# NUC505_v1 register map
File version: 1.0
Registers are 32-bit, read-write, reset 0x0 unless marked. A register's access mark holds for its fields unless they carry their own. Offsets are from the block's base; [hi:lo] are bit positions; {n}, {i} and the like mark numbered series; 'fields as' and 'values as' point back to an identical list.

## UART0 — UART Register Map
Base 0x400EC000
0x00 UART_DAT reset not defined — UART Receive/Transmit Buffer Register
  [7:0] DAT — Receiving/Transmit Buffer. Write Operation: By writing one byte to this register, the data byte will be stored in transmitter FIFO. The UART Controller will send out the data stored in transmitter FIFO top location through the UART_TXD. Read Operation: By reading this register, the UART will return an 8-bit data received from receiving FIFO.
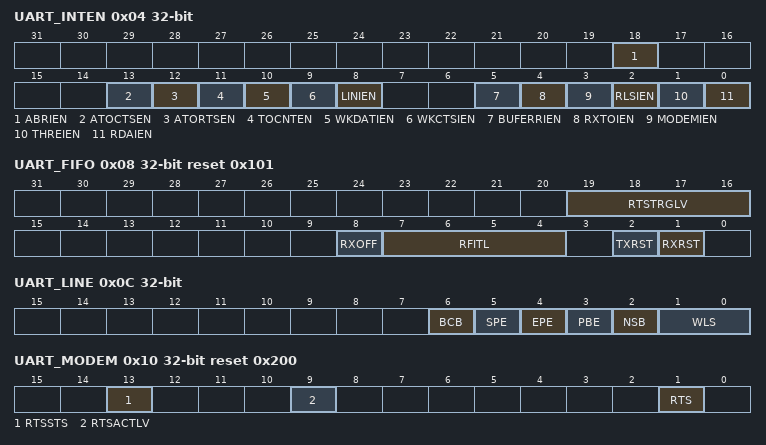
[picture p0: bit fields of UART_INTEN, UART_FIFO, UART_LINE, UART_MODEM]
0x04 UART_INTEN — UART Interrupt Enable Register
  [18] ABRIEN — Auto-baud Rate Interrupt Enable Control
    0=Auto-baud rate interrupt Disabled; 1=Auto-baud rate interrupt Enabled
  [13] ATOCTSEN — nCTS Auto-flow Control Enable Control. When nCTS auto-flow is enabled, the UART will send data to external device if nCTS input assert (UART will not send data to device until nCTS is asserted).
    0=nCTS auto-flow control Disabled; 1=nCTS auto-flow control Enabled
  [12] ATORTSEN — nRTS Auto-flow Control Enable Control. When nRTS auto-flow is enabled, if the number of bytes in the RX FIFO equals the RTSTRGLV (UART_FIFO[19:16]), the UART will de-assert nRTS signal.
    0=nRTS auto-flow control Disabled; 1=nRTS auto-flow control Enabled
  [11] TOCNTEN — Time-out Counter Enable Control
    0=Time-out counter Disabled; 1=Time-out counter Enabled
  [10] WKDATIEN — Incoming Data Wake-up Interrupt Enable Control. Hardware will clear this bit when the incoming data wake-up operation finishes and "system clock" work stable.
    0=Incoming data wake-up system function Disabled; 1=Incoming data wake-up system function Enabled. When the system is in Power-down mode, incoming data will wake up system from Power-down mode.
  [9] WKCTSIEN — nCTS Wake-up Interrupt Enable Control
    0=nCTS wake-up system function Disabled; 1=Wake-up system function Enabled. When the system is in Power-down mode, an external nCTS change will wake up system from Power-down mode
  [8] LINIEN — LIN Bus Interrupt Enable Control (Not Available in UART1/UART2). This bit is used for LIN function mode.
    0=LIN bus interrupt Disabled; 1=LIN bus interrupt Enabled
  [5] BUFERRIEN — Buffer Error Interrupt Enable Control
    0=Buffer error interrupt Disabled; 1=Buffer error interrupt Enabled
  [4] RXTOIEN — RX Time-out Interrupt Enable Control
    0=RX time-out interrupt Disabled; 1=RX time-out interrupt Enabled
  [3] MODEMIEN — Modem Status Interrupt Enable Control
    0=Modem status interrupt Disabled; 1=Modem status interrupt Enabled
  [2] RLSIEN — Receive Line Status Interrupt Enable Control
    0=Receive Line Status interrupt Disabled; 1=Receive Line Status interrupt Enabled
  [1] THREIEN — Transmit Holding Register Empty Interrupt Enable Control
    0=Transmit holding register empty interrupt Disabled; 1=Transmit holding register empty interrupt Enabled
  [0] RDAIEN — Receive Data Available Interrupt Enable Control
    0=Receive data available interrupt Disabled; 1=Receive data available interrupt Enabled
0x08 UART_FIFO reset 0x101 — UART FIFO Control Register
  [19:16] RTSTRGLV — nRTS Trigger Level for Auto-flow Control Use. Note: This field is used for automatic nRTS flow control.
    0=nRTS Trigger Level is 1 bytes; 1=nRTS Trigger Level is 4bytes; 2=nRTS Trigger Level is 8 bytes; 3=nRTS Trigger Level is 14 bytes; 4=nRTS Trigger Level is 30/14 (64 FIFO/16 FIFO); 5=nRTS Trigger Level is 46/14 (64 FIFO/16 FIFO); 6=nRTS Trigger Level is 62/14 (64 FIFO/16 FIFO)
  [8] RXOFF — Receiver Disable Control. The receiver is disabled or not (set 1 to disable receiver). Note: This bit is used for RS-485 Normal Multi-drop mode. It should be programmed before RS485NMM (UART_ALTCTL [8]) is programmed.
    0=Receiver Enabled; 1=Receiver Disabled
  [7:4] RFITL — RX FIFO Interrupt Trigger Level. When the number of bytes in the receive FIFO equals the RFITL, the RDAIF will be set (if RDAIEN (UART_INTEN [0]) enabled, and an interrupt will be generated).
    0=RX FIFO Interrupt Trigger Level is 1 byte; 1=RX FIFO Interrupt Trigger Level is 4 bytes; 2=RX FIFO Interrupt Trigger Level is 8 bytes; 3=RX FIFO Interrupt Trigger Level is 14 bytes; 4=RX FIFO Interrupt Trigger Level is 30/14 (64 FIFO/16 FIFO); 5=RX FIFO Interrupt Trigger Level is 46/14 (64 FIFO/16 FIFO); 6=RX FIFO Interrupt Trigger Level is 62/14 (64 FIFO/16 FIFO)
  [2] TXRST — TX Field Software Reset Control. When TXRST (UART_FIFO[2]) is set, all the byte in the transmit FIFO and TX internal state machine are cleared. Note: This bit will automatically clear at least 3 UART peripheral clock cycles.
    0=No effect; 1=Reset the TX internal state machine and pointers
  [1] RXRST — RX Field Software Reset Control. When RXRST (UART_FIFO[1]) is set, all the byte in the receiver FIFO and RX internal state machine are cleared. Note: This bit will automatically clear at least 3 UART peripheral clock cycles.
    0=No effect; 1=Reset the RX internal state machine and pointers
0x0C UART_LINE — UART Line Control Register
  [6] BCB — Break Control. Note: When this bit is set to logic 1, the serial data output (TX) is forced to the Spacing State (logic 0). This bit acts only on TX line and has no effect on the transmitter logic.
    0=Break Control Disabled; 1=Break Control Enabled
  [5] SPE — Stick Parity Enable Control. Note: If PBE (UART_LINE[3]) and EPE (UART_LINE[4]) are logic 1, the parity bit is transmitted and checked as logic 0. If PBE (UART_LINE[3]) is 1 and EPE (UART_LINE[4]) is 0 then the parity bit is transmitted and checked as 1.
    0=Stick parity Disabled; 1=Stick parity Enabled
  [4] EPE — Even Parity Enable Control. Note: This bit is effective only when PBE (UART_LINE[3]) is set.
    0=Odd number of logic 1's is transmitted and checked in each word; 1=Even number of logic 1's is transmitted and checked in each word
  [3] PBE — Parity Bit Enable Control. Note: Parity bit is generated on each outgoing character and is checked on each incoming data.
    0=No parity bit generated Disabled; 1=Parity bit generated Enabled
  [2] NSB — Number of "STOP Bit"
    0=One "STOP bit" is generated in the transmitted data; 1=When select 5-bit word length, 1.5 "STOP bit" is generated in the transmitted data. When select 6-, 7- and 8-bit word length, 2 "STOP bit" is generated in the transmitted data
  [1:0] WLS — Word Length Selection. This field sets UART word length.
    {v}={v+5} bits (v=0..3)
0x10 UART_MODEM reset 0x200 — UART Modem Control Register
  [13] RTSSTS ro — nRTS Pin Status (Read Only). This bit mirror from nRTS pin output of voltage logic status.
    0=nRTS pin output is low level voltage logic state; 1=nRTS pin output is high level voltage logic state
  [9] RTSACTLV — nRTS Pin Active Level. This bit defines the active level state of nRTS pin output. Note1: Refer to Figure 6.1010 and Figure 6.1011 for UART function mode. Note2: Refer to Figure 6.1021 and Figure 6.1022 for RS-485 function mode.
    0=nRTS pin output is high level active; 1=nRTS pin output is low level active. (Default)
  [1] RTS — nRTS (Request-to-send) Signal Control. This bit is direct control internal nRTS signal active or not, and then drive the nRTS pin output with RTSACTLV bit configuration. Note1: This nRTS signal control bit is not effective when nRTS auto-flow control is enabled in UART function mode. Note2: This nRTS signal control bit is not effective when RS-485 auto direction mode (AUD) is enabled in RS-485 function mode.
    0=nRTS signal is active; 1=nRTS signal is inactive
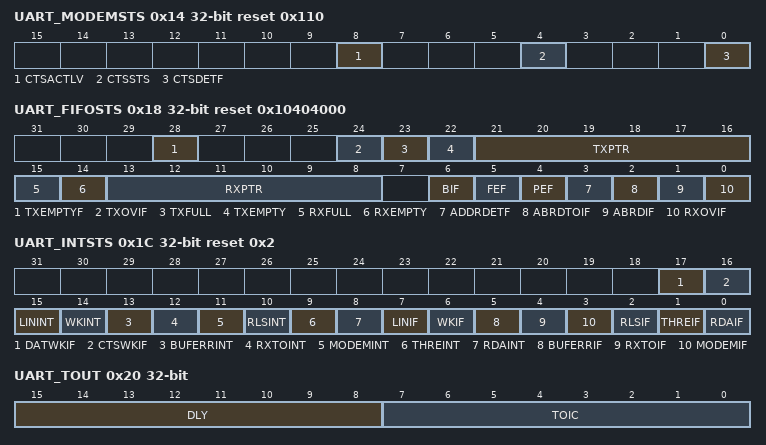
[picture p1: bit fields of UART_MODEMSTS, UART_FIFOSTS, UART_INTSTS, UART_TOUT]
0x14 UART_MODEMSTS reset 0x110 — UART Modem Status Register
  [8] CTSACTLV — nCTS Pin Active Level. This bit defines the active level state of nCTS pin input.
    0=nCTS pin input is high level active; 1=nCTS pin input is low level active. (Default)
  [4] CTSSTS ro — nCTS Pin Status (Read Only). This bit mirror from nCTS pin input of voltage logic status. Note: This bit echoes when UART Controller peripheral clock is enabled, and nCTS multi-function port is selected.
    0=nCTS pin input is low level voltage logic state; 1=nCTS pin input is high level voltage logic state
  [0] CTSDETF ro — Detect nCTS State Change Flag (Read Only). This bit is set whenever nCTS input has change state, and it will generate Modem interrupt to CPU when MODEMIEN (UART_INTEN [3]) is set to 1. Note: This bit is read only, but can be cleared by writing "1" to it.
    0=nCTS input has not change state; 1=nCTS input has change state
0x18 UART_FIFOSTS reset 0x10404000 — UART FIFO Status Register
  [28] TXEMPTYF ro — Transmitter Empty Flag (Read Only). This bit is set by hardware when TX FIFO (UART_DAT) is empty and the STOP bit of the last byte has been transmitted. Note: This bit is cleared automatically when TX FIFO is not empty or the last byte transmission has not completed.
    0=TX FIFO is not empty; 1=TX FIFO is empty
  [24] TXOVIF ro — TX Overflow Error Interrupt Flag (Read Only). If TX FIFO (UART_DAT) is full, an additional write to UART_DAT will cause this bit to logic 1. Note: This bit is read only, but can be cleared by writing "1" to it.
    0=TX FIFO is not overflow; 1=TX FIFO is overflow
  [23] TXFULL ro — Transmitter FIFO Full (Read Only). This bit indicates TX FIFO full or not. Note: This bit is set when the number of usage in TX FIFO Buffer is equal to 16/64, otherwise is cleared by hardware.
    0=TX FIFO is not full; 1=TX FIFO is full
  [22] TXEMPTY ro — Transmitter FIFO Empty (Read Only). This bit indicates TX FIFO empty or not. Note: When the last byte of TX FIFO has been transferred to Transmitter Shift Register, hardware sets this bit high. It will be cleared when writing data into DAT (TX FIFO not empty).
    0=TX FIFO is not empty; 1=TX FIFO is empty
  [21:16] TXPTR ro — TX FIFO Pointer (Read Only). This field indicates the TX FIFO Buffer Pointer. When CPU writes one byte into UART_DAT, TXPTR increases one. When one byte of TX FIFO is transferred to Transmitter Shift Register, TXPTR decreases one. The Maximum value shown in TXPTR is 15/63. When the using level of TX FIFO Buffer equal to 16/64, the TXFULL bit is set to 1 and TXPTR will show 0. As one byte of TX FIFO is transferred to Transmitter Shift Register, the TXFULL bit is cleared to 0 and TXPTR will show 15/63.
  [15] RXFULL ro — Receiver FIFO Full (Read Only). This bit initiates RX FIFO full or not. Note: This bit is set when the number of usage in RX FIFO Buffer is equal to 16/64, otherwise is cleared by hardware.
    0=RX FIFO is not full; 1=RX FIFO is full
  [14] RXEMPTY ro — Receiver FIFO Empty (Read Only). This bit initiate RX FIFO empty or not. Note: When the last byte of RX FIFO has been read by CPU, hardware sets this bit high. It will be cleared when UART receives any new data.
    0=RX FIFO is not empty; 1=RX FIFO is empty
  [13:8] RXPTR ro — RX FIFO Pointer (Read Only). This field indicates the RX FIFO Buffer Pointer. When UART receives one byte from external device, RXPTR increases one. When one byte of RX FIFO is read by CPU, RXPTR decreases one. The Maximum value shown in RXPTR is 15/63. When the using level of RX FIFO Buffer equal to 16/64, the RXFULL bit is set to 1 and RXPTR will show 0. As one byte of RX FIFO is read by CPU, the RXFULL bit is cleared to 0 and RXPTR will show 15/63.
  [6] BIF ro — Break Interrupt Flag (Read Only). This bit is set to logic 1 whenever the received data input (RX) is held in the "spacing state" (logic 0) for longer than a full word transmission time (that is, the total time of "start bit" + data bits + parity + stop bits). Note: This bit is read only, but can be cleared by writing '1' to it.
    0=No Break interrupt is generated; 1=Break interrupt is generated
  [5] FEF ro — Framing Error Flag (Read Only). This bit is set to logic 1 whenever the received character does not have a valid "stop bit" (that is, the stop bit following the last data bit or parity bit is detected as logic 0). Note: This bit is read only, but can be cleared by writing '1' to it.
    0=No framing error is generated; 1=Framing error is generated
  [4] PEF ro — Parity Error Flag (Read Only). This bit is set to logic 1 whenever the received character does not have a valid "parity bit". Note: This bit is read only, but can be cleared by writing '1' to it.
    0=No parity error is generated; 1=Parity error is generated
  [3] ADDRDETF ro — RS-485 Address Byte Detect Flag (Read Only). Note1: This field is used for RS-485 function mode and ADDRDEN (UART_ALTCTL[15]) is set to 1 to enable Address detection mode. Note2: This bit is read only, but can be cleared by writing '1' to it.
    0=Receiver detects a data that is not an address bit (bit 9 ='0'); 1=Receiver detects a data that is an address bit (bit 9 ='1')
  [2] ABRDTOIF ro — Auto-baud Rate Time-out Interrupt (Read Only). Note1: This bit is set to logic "1" in Auto-baud Rate Detect mode and the baud rate counter is overflow. Note2: This bit is read only, but can be cleared by writing "1" to it.
    0=Auto-baud rate counter is underflow; 1=Auto-baud rate counter is overflow
  [1] ABRDIF ro — Auto-baud Rate Detect Interrupt (Read Only). Note1: This bit is set to logic "1" when auto-baud rate detect function is finished. Note2: This bit is read only, but can be cleared by writing "1" to it.
    0=Auto-baud rate detect function is not finished; 1=Auto-baud rate detect function is finished
  [0] RXOVIF ro — RX Overflow Error Interrupt Flag (Read Only). This bit is set when RX FIFO overflow. If the number of bytes of received data is greater than RX_FIFO (UART_DAT) size, 16/64 bytes this bit will be set. Note: This bit is read only, but can be cleared by writing "1" to it.
    0=RX FIFO is not overflow; 1=RX FIFO is overflow
0x1C UART_INTSTS reset 0x2 — UART Interrupt Status Register
  [17] DATWKIF ro — Data Wake-up Interrupt Flag (Read Only). This bit is set if chip wake-up from Power-down state by data wake-up. Note1: If WKDATIEN (UART_INTEN[10]) is enabled, the wake-up interrupt is generated. Note2: This bit is read only, but can be cleared by writing '1' to it.
    0=Chip stays in Power-down state; 1=Chip wake-up from Power-down state by data wake-up
  [16] CTSWKIF ro — nCTS Wake-up Interrupt Flag (Read Only). Note1: If WKCTSIEN (UART_INTEN[9])is enabled, the wake-up interrupt is generated. Note2: This bit is read only, but can be cleared by writing '1' to it.
    0=Chip stays in Power-down state; 1=Chip wake-up from Power-down state by nCTS wake-up
  [15] LININT ro — LIN Bus Interrupt Indicator (Read Only)(Not Available in UART0 Channel). This bit is set if LINIEN (UART_INTEN[8]) and LIN IF(UART_INTSTS[7]) are both set to 1.
    0=No LIN Bus interrupt is generated; 1=The LIN Bus interrupt is generated
  [14] WKINT ro — UART Wake-up Interrupt Indicator (Read Only). This bit is set when DATWKIF or CTSWKIF is set to 1.
    0=NO data or nCTS wake-up interrupt are generated; 1=Data or nCTS wake-up interrupt are generated
  [13] BUFERRINT ro — Buffer Error Interrupt Indicator (Read Only). This bit is set if BFERRIEN(UART_INTEN[5] and BUFERRIF(UART_INTSTS[5]) are both set to 1.
    0=No buffer error interrupt is generated; 1=Buffer error interrupt is generated
  [12] RXTOINT ro — Time-out Interrupt Indicator (Read Only). This bit is set if TOUTIEN(UART_INTEN[4]) and RXTOIF(UART_INTSTS[4]) are both set to 1.
    0=No Tout interrupt is generated; 1=Tout interrupt is generated
  [11] MODEMINT ro — MODEM Status Interrupt Indicator (Read Only). This bit is set if MODEMIEN(UART_INTEN[3] and MODEMIF(UART_INTSTS[4]) are both set to 1
    0=No Modem interrupt is generated; 1=Modem interrupt is generated
  [10] RLSINT ro — Receive Line Status Interrupt Indicator (Read Only). This bit is set if RLSIEN (UART_INTEN[2]) and RLSIF(UART_INTSTS[2]) are both set to 1.
    0=No RLS interrupt is generated; 1=RLS interrupt is generated
  [9] THREINT ro — Transmit Holding Register Empty Interrupt Indicator (Read Only). This bit is set if THREIEN (UART_INTEN[1])and THREIF(UART_INTSTS[1]) are both set to 1.
    0=No DATE interrupt is generated; 1=DATE interrupt is generated
  [8] RDAINT ro — Receive Data Available Interrupt Indicator (Read Only). This bit is set if RDAIEN (UART_INTEN[0]) and RDAIF (UART_INTSTS[0]) are both set to 1.
    0=No RDA interrupt is generated; 1=RDA interrupt is generated
  [7] LINIF ro — LIN Bus Interrupt Flag (Read Only) (Not Available in UART0 Channel). Note: This bit is read only. This bit is cleared when SLVHDETF(UART_LINSTS[0]), BRKDETF(UART_LINSTS[8]), BITEF(UART_LINSTS[9]), SLVIDPEF (UART_LINSTS[2]), SLVHEF(UART_LINSTS[1]) and SLVSYNCF(UART_LINSTS[3]) all are cleared.
    0=None of SLVHDETF, BRKDETF, BITEF, SLVIDPEF and SLVHEF is generated; 1=At least one of SLVHDETF, BRKDETF, BITEF, SLVIDPEF and SLVHEF is generated
  [6] WKIF ro — UART Wake-up Interrupt Flag (Read Only). This bit is set when DATWKIF (UART_INTSTS[17]) or CTSWKIF(UART_INTSTS[16]) is set to 1. Note: This bit is read only. This bit is cleared if both of DATWKIF (UART_INTSTS[17]) and CTSWKIF(UART_INTSTS[16]) are cleared to 0 by writing 1 to DATWKIF (UART_INTSTS[17]) and CTSWKIF (UART_INTSTS[17]).
    0=No DATWKIF and CTSWKIF are generated; 1=DATWKIF or CTSWKIF
  [5] BUFERRIF ro — Buffer Error Interrupt Flag (Read Only). This bit is set when the TX FIFO or RX FIFO overflows (TXOVIF (UART_FIFOSTS[24]) or RXOVIF (UART_FIFOSTS[0]) is set). When BUFERRIF (UART_INTSTS[5])is set, the transfer is not correct. If BFERRIEN (UART_INTEN [8]) is enabled, the buffer error interrupt will be generated. Note: This bit is read only. This bit is cleared if both of RXOVIF(UART_FIFOSTS[0]) and TXOVIF(UART_FIFOSTS[24]) are cleared to 0 by writing 1 to RXOVIF(UART_FIFOSTS[0]) and TXOVIF(UART_FIFOSTS[24]).
    0=No buffer error interrupt flag is generated; 1=Buffer error interrupt flag is generated
  [4] RXTOIF ro — Time-out Interrupt Flag (Read Only). This bit is set when the RX FIFO is not empty and no activities occurred in the RX FIFO and the time-out counter equal to TOIC. If TOUTIEN (UART_INTEN [4]) is enabled, the Tout interrupt will be generated. Note: This bit is read only and user can read UART_DAT (RX is in active) to clear it.
    0=No Time-out interrupt flag is generated; 1=Time-out interrupt flag is generated
  [3] MODEMIF ro — MODEM Interrupt Flag (Read Only) Channel. Note: This bit is read only and reset to 0 when bit CTSDETF is cleared by a write 1 on CTSDETF(UART_MODEMSTS[0]).
    0=No Modem interrupt flag is generated; 1=Modem interrupt flag is generated
  [2] RLSIF ro — Receive Line Interrupt Flag (Read Only). This bit is set when the RX receive data have parity error, frame error or break error (at least one of 3 bits, BIF(UART_FIFOSTS[6]), FEF(UART_FIFOSTS[5]) and PEF(UART_FIFOSTS[4]), is set). If RLSIEN (UART_INTEN [2]) is enabled, the RLS interrupt will be generated. Note2: This bit is read only and reset to 0 when all bits of BIF (UART_FIFOSTS[6]), FEF(UART_FIFOSTS[5]) and PEF(UART_FIFOSTS[4]) are cleared. Note3: In RS-485 function mode, this bit is read only and reset to 0 when all bits of BIF (UART_FIFOSTS[6]) , FEF(UART_FIFOSTS[5]) and PEF(UART_FIFOSTS[4]) and ADDRDETF (UART_FIFOSTS[3]) are cleared.
    0=No RLS interrupt flag is generated; 1=RLS interrupt flag is generated
  [1] THREIF ro — Transmit Holding Register Empty Interrupt Flag (Read Only). This bit is set when the last data of TX FIFO is transferred to Transmitter Shift Register. If THREIEN (UART_INTEN[1]) is enabled, the THRE interrupt will be generated. Note: This bit is read only and it will be cleared when writing data into UART_DAT (TX FIFO not empty).
    0=No THRE interrupt flag is generated; 1=THRE interrupt flag is generated
  [0] RDAIF ro — Receive Data Available Interrupt Flag (Read Only). When the number of bytes in the RX FIFO equals the RFITL then the RDAIF(UART_INTSTS[0]) will be set. If RDAIEN (UART_INTEN [0]) is enabled, the RDA interrupt will be generated. Note: This bit is read only and it will be cleared when the number of unread bytes of RX FIFO drops below the threshold level (RFITL(UART_FIFO[7:4]).
    0=No RDA interrupt flag is generated; 1=RDA interrupt flag is generated
0x20 UART_TOUT — UART Time-out Register
  [15:8] DLY — TX Delay Time Value. This field is used to programming the transfer delay time between the last stop bit and next start bit. The unit is bit time.
  [7:0] TOIC — Time-out Interrupt Comparator
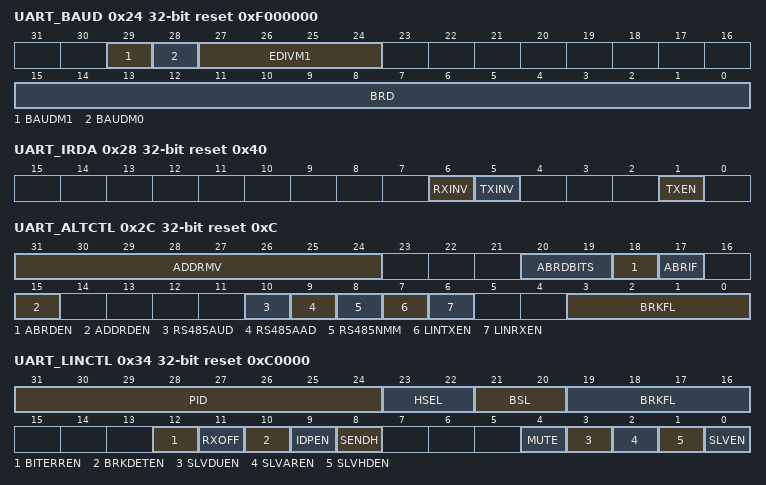
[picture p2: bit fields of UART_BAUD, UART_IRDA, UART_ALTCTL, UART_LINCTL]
0x24 UART_BAUD reset 0xF000000 — UART Baud Rate Divisor Register
  [29] BAUDM1 — BAUD Rate Mode Selection Bit 1. This bit is baud rate mode selection bit 1. UART provides three baud rate calculation modes. This bit combines with BAUDM0 (UART_BAUD[28]) to select baud rate calculation mode. The detail description is shown in Table 6.102. In IrDA mode must be operated in mode 0.
  [28] BAUDM0 — BAUD Rate Mode Selection Bit 0. This bit is baud rate mode selection bit 0. UART provides three baud rate calculation modes. This bit combines with BAUDM1 (UART_BAUD[29]) to select baud rate calculation mode. The detail description is shown in Table 6.102.
  [27:24] EDIVM1 — Extra Divider for BAUD Rate Mode 1. This field is used for baud rate calculation in mode 1 and has no effect for baud rate calculation in mode 0 and mode 2. The detail description is shown in Table 6.102.
  [15:0] BRD — Baud Rate Divider. The field indicates the baud rate divider. This filed is used in baud rate calculation. The detail description is shown in Table 6.102.
0x28 UART_IRDA reset 0x40 — UART IrDA Control Register
  [6] RXINV — IrDA Inverse Receive Input Signal
    0=None inverse receiving input signal; 1=Inverse receiving input signal. (Default)
  [5] TXINV — IrDA Inverse Transmitting Output Signal
    0=None inverse transmitting signal. (Default); 1=Inverse transmitting output signal
  [1] TXEN — IrDA Receiver/Transmitter Selection Enable Control
    0=IrDA Transmitter Disabled and Receiver Enabled. (Default); 1=IrDA Transmitter Enabled and Receiver Disabled
0x2C UART_ALTCTL reset 0xC — UART Alternate Control/Status Register
  [31:24] ADDRMV — Address Match Value. This field contains the RS-485 address match values. This field is used for RS-485 auto address detection mode.
  [20:19] ABRDBITS — Auto-baud Rate Detect Bit Length. Note: The calculation of bit number includes the START bit.
    0=1-bit time from Start bit to the 1st rising edge. The input pattern shall be 0x01; 1=2-bit time from Start bit to the 1st rising edge. The input pattern shall be 0x02; 2=4-bit time from Start bit to the 1st rising edge. The input pattern shall be 0x08; 3=8-bit time from Start bit to the 1st rising edge. The input pattern shall be 0x80
  [18] ABRDEN — Auto-baud Rate Detect Enable Control. Note: This bit is cleared automatically after auto-baud detection is finished.
    0=Auto-baud rate detect function Disabled; 1=Auto-baud rate detect function Enabled
  [17] ABRIF ro — Auto-baud Rate Interrupt Flag (Read Only). This bit is set when auto-baud rate detection function finished or the auto-baud rate counter was overflow and if ABRIEN(UART_INTEN [18]) is set then the auto-baud rate interrupt will be generated. Note: This bit is read only, but it can be cleared by writing "1" to ABRDTOIF (UART_FIFOSTS[2]) and ABRDIF(UART_FIFOSTS[1]).
  [15] ADDRDEN — RS-485 Address Detection Enable Control. This bit is used to enable RS-485 Address Detection mode. Note: This bit is used for RS-485 any operation mode.
    0=Address detection mode Disabled; 1=Address detection mode Enabled
  [10] RS485AUD — RS-485 Auto Direction Function (AUD). Note: It can be active with RS-485_AAD or RS-485_NMM operation mode.
    0=RS-485 Auto Direction Operation function (AUD) Disabled; 1=RS-485 Auto Direction Operation function (AUD) Enabled
  [9] RS485AAD — RS-485 Auto Address Detection Operation Mode (AAD). It cannot be active with RS-485_NMM operation mode.
    0=RS-485 Auto Address Detection Operation mode (AAD) Disabled; 1=RS-485 Auto Address Detection Operation mode (AAD) Enabled
  [8] RS485NMM — RS-485 Normal Multi-drop Operation Mode (NMM). Note: It cannot be active with RS-485_AAD operation mode.
    0=RS-485 Normal Multi-drop Operation mode (NMM) Disabled; 1=RS-485 Normal Multi-drop Operation mode (NMM) Enabled
  [7] LINTXEN — LIN TX Break Mode Enable Control (Only Available in UART1/UART2 Channel). Note: When TX break field transfer operation finished, this bit will be cleared automatically.
    0=LIN TX Break mode Disabled; 1=LIN TX Break mode Enabled
  [6] LINRXEN — LIN RX Enable Control (Only Available in UART1/UART2 Channel)
    0=LIN RX mode Disabled; 1=LIN RX mode Enabled
  [3:0] BRKFL — UART LIN Break Field Length (Only Available in UART1/UART2 Channel). This field indicates a 4-bit LIN TX break field count. Note1: This break field length is BRKFL + 1
0x30 UART_FUNCSEL — UART Function Select Register
  [1:0] FUNCSEL — Function Select
    0=UART function; 1=LIN function (Only Available in UART1/UART2 Channel); 2=IrDA function; 3=RS-485 function
0x34 UART_LINCTL reset 0xC0000 — UART LIN Control Register *
  [31:24] PID — LIN PID Bits. If the parity generated by hardware, and user fills in ID0~ID5, (PID [29:24]), hardware will calculate P0 (PID[30]) and P1 (PID[31]), otherwise user must fill a frame ID and parity in this field. Note1: User can fill in any 8-bit value to this field and the bit 24 indicates ID0 (LSB first). Note2: This field can be used for LIN Master mode or Slave mode.
  [23:22] HSEL — LIN Header Select
    0=The LIN header includes "break field"; 1=The LIN header includes "break field" and "sync field"; 2=The LIN header includes "break field", "sync field" and "frame ID field"
  [21:20] BSL — LIN Break/Sync Delimiter Length. Note: This bit is used for LIN master to send header field.
    {v}=The LIN break/sync delimiter length is {v+1}-bit time (v=0..3)
  [19:16] BRKFL — LIN Break Field Length. This field indicates a 4-bit LIN TX break field count. Note1: These registers are shadow registers of BRKFL, User can read/write it by setting BRKFL (UART_ALTCTL[3:0]) or BRKFL (UART_LINCTL[19:16]). Note2: This break field length is BRKFL + 1.
  [12] BITERREN — Bit Error Detect Enable Control
    0=Bit error detection function Disabled; 1=Bit error detection Enabled
  [11] RXOFF — LIN Receiver Disable Control
    0=LIN receiver Enabled; 1=LIN receiver Disabled
  [10] BRKDETEN — LIN Break Detection Enable Control
    0=LIN break detection Disabled; 1=LIN break detection Enabled
  [9] IDPEN — LIN ID Parity Enable Control
    0=LIN frame ID parity Disabled; 1=LIN frame ID parity Enabled
  [8] SENDH — LIN TX Send Header Enable Control. The LIN TX header can be "break field" or "break and sync field" or "break, sync and frame ID field", it is depend on setting HSEL (UART_LINCTL[23:22]). Note1: These registers are shadow registers of LINTXEN (UART_ALTCTL [7]); user can read/write it by setting LINTXEN (UART_ALTCTL [7]) or SENDH (UART_LINCTL [8]). Note2: When transmitter header field (it may be "break" or "break + sync" or "break + sync + frame ID" selected by HSEL (UART_LINCTL[23:22]) field) transfer operation finished, this bit will be cleared automatically.
    0=Send LIN TX header Disabled; 1=Send LIN TX header Enabled
  [4] MUTE — LIN Mute Mode Enable Control. Note: The exit from mute mode condition and each control and interactions of this field are explained in 6.10.5.9 (LIN Slave mode).
    0=LIN mute mode Disabled; 1=LIN mute mode Enabled
  [3] SLVDUEN — LIN Slave Divider Update Method Enable Control. Note2: This bit is used for LIN Slave Automatic Resynchronization mode. (for Non-Automatic Resynchronization mode, this bit should be kept cleared). Note3: The control and interactions of this field are explained in 6.10.5.9 (Slave mode with automatic resynchronization).
    0=UART_BAUD updated is written by software (if no automatic resynchronization update occurs at the same time); 1=UART_BAUD is updated at the next received character. User must set the bit before checksum reception
  [2] SLVAREN — LIN Slave Automatic Resynchronization Mode Enable Control. Note2: When operating in Automatic Resynchronization mode, the baud rate setting must be mode2 (BAUDM1 (UART_BAUD [29]) and BAUDM0 (UART_BAUD [28]) must be 1). Note3: The control and interactions of this field are explained in 6.10.5.9(Slave mode with automatic resynchronization).
    0=LIN automatic resynchronization Disabled; 1=LIN automatic resynchronization Enabled
  [1] SLVHDEN — LIN Slave Header Detection Enable Control
    0=LIN slave header detection Disabled; 1=LIN slave header detection Enabled
  [0] SLVEN — LIN Slave Mode Enable Control
    0=LIN Slave mode Disabled; 1=LIN Slave mode Enabled
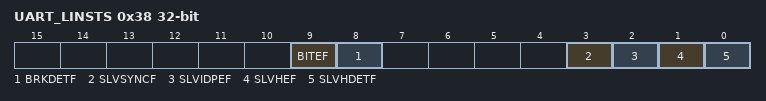
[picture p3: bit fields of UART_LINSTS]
0x38 UART_LINSTS — UART LIN Status Register *
  [9] BITEF ro — Bit Error Detect Status Flag (Read Only). At TX transfer state, hardware will monitoring the bus state, if the input pin (SIN) state not equals to the output pin (SOUT) state, BITEF (UART_LINSTS[9]) will be set.
  [8] BRKDETF ro — LIN Break Detection Flag (Read Only). This bit is set by hardware when a break is detected and be cleared by writing 1 to it through software.
    0=LIN break not detected; 1=LIN break detected
  [3] SLVSYNCF ro — LIN Slave Sync Field (Read Only). This bit indicates that the LIN sync field is being analyzed in Automatic Resynchronization mode. When the receiver header have some error been detect, user must reset the internal circuit to re-search new frame header by writing 1 to this bit. Note2: This bit is read only, but it can be cleared by writing 1 to it. Note3: When writing 1 to it, hardware will reload the initial baud rate and re-search a new frame header.
    0=The current character is not at LIN sync state; 1=The current character is at LIN sync state
  [2] SLVIDPEF — LIN Slave ID Parity Error Flag. This bit is set by hardware when receipted frame ID parity is not correct.
    0=No active; 1=Receipted frame ID parity is not correct
  [1] SLVHEF ro — LIN Slave Header Error Flag (Read Only). This bit is set by hardware when a LIN header error is detected in LIN Slave mode and be cleared by writing 1 to it. The header errors include "break delimiter is too short (less than 0.5 bit time)", "frame error in sync field or Identifier field", "sync field data is not 0x55 in Non-Automatic Resynchronization mode", "sync field deviation error with Automatic Resynchronization mode", "sync field measure time-out with Automatic Resynchronization mode" and "LIN header reception time-out".
    0=LIN header error not detected; 1=LIN header error detected
  [0] SLVHDETF ro — LIN Slave Header Detection Flag (Read Only). This bit is set by hardware when a LIN header is detected in LIN Slave mode and be cleared by writing 1 to it. Note3: When enable ID parity check IDPEN (UART_LINCTL [9]), if hardware detect complete header ("break + sync + frame ID"), the SLVHDETF will be set whether the frame ID correct or not.
    0=LIN header not detected; 1=LIN header detected (break + sync + frame ID)

## UART1 — UART Register Map
Base 0x400ED000
Registers as UART0; these are added or differ:
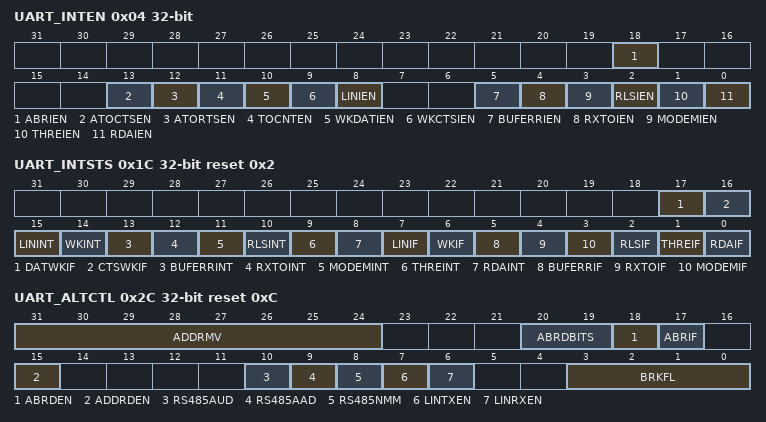
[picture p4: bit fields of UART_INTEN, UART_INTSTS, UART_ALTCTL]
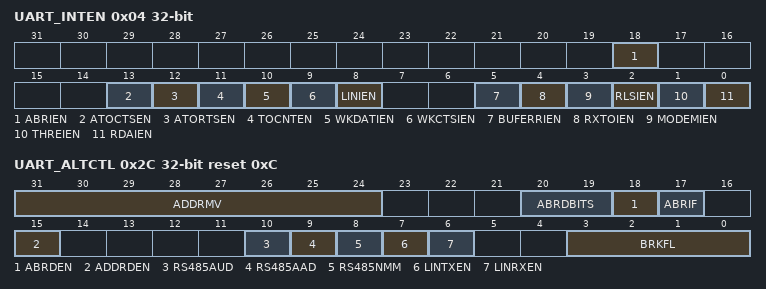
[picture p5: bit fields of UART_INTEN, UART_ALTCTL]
0x04 UART_INTEN — UART Interrupt Enable Register
  [18] ABRIEN — Auto-baud Rate Interrupt Enable Control
    0=Auto-baud rate interrupt Disabled; 1=Auto-baud rate interrupt Enabled
  [13] ATOCTSEN — nCTS Auto-flow Control Enable Control. When nCTS auto-flow is enabled, the UART will send data to external device if nCTS input assert (UART will not send data to device until nCTS is asserted).
    0=nCTS auto-flow control Disabled; 1=nCTS auto-flow control Enabled
  [12] ATORTSEN — nRTS Auto-flow Control Enable Control. When nRTS auto-flow is enabled, if the number of bytes in the RX FIFO equals the RTSTRGLV (UART_FIFO[19:16]), the UART will de-assert nRTS signal.
    0=nRTS auto-flow control Disabled; 1=nRTS auto-flow control Enabled
  [11] TOCNTEN — Time-out Counter Enable Control
    0=Time-out counter Disabled; 1=Time-out counter Enabled
  [10] WKDATIEN — Incoming Data Wake-up Interrupt Enable Control. Hardware will clear this bit when the incoming data wake-up operation finishes and "system clock" work stable.
    0=Incoming data wake-up system function Disabled; 1=Incoming data wake-up system function Enabled. When the system is in Power-down mode, incoming data will wake up system from Power-down mode
  [9] WKCTSIEN — nCTS Wake-up Interrupt Enable Control
    0=nCTS wake-up system function Disabled; 1=Wake-up system function Enabled. When the system is in Power-down mode, an external nCTS change will wake up system from Power-down mode
  [8] LINIEN — LIN Bus Interrupt Enable Control (Not Available in UART1/UART2). This bit is used for LIN function mode.
    0=LIN bus interrupt Disabled; 1=LIN bus interrupt Enabled
  [5] BUFERRIEN — Buffer Error Interrupt Enable Control
    0=Buffer error interrupt Disabled; 1=Buffer error interrupt Enabled
  [4] RXTOIEN — RX Time-out Interrupt Enable Control
    0=RX time-out interrupt Disabled; 1=RX time-out interrupt Enabled
  [3] MODEMIEN — Modem Status Interrupt Enable Control
    0=Modem status interrupt Disabled; 1=Modem status interrupt Enabled
  [2] RLSIEN — Receive Line Status Interrupt Enable Control
    0=Receive Line Status interrupt Disabled; 1=Receive Line Status interrupt Enabled
  [1] THREIEN — Transmit Holding Register Empty Interrupt Enable Control
    0=Transmit holding register empty interrupt Disabled; 1=Transmit holding register empty interrupt Enabled
  [0] RDAIEN — Receive Data Available Interrupt Enable Control
    0=Receive data available interrupt Disabled; 1=Receive data available interrupt Enabled
0x1C UART_INTSTS reset 0x2 — UART Interrupt Status Register
  fields as UART0.UART_INTSTS
0x2C UART_ALTCTL reset 0xC — UART Alternate Control/Status Register
  fields as UART0.UART_ALTCTL
0x30 UART_FUNCSEL — UART Function Select Register
  [1:0] FUNCSEL — Function Select
    0=UART function; 1=LIN function (Only Available in UART1/UART2 Channel); 2=IrDA function; 3=RS-485 function

## UART2 — UART Register Map
Base 0x400EE000
Registers as UART1; these are added or differ:
0x04 UART_INTEN — UART Interrupt Enable Register
  fields as UART1.UART_INTEN
0x2C UART_ALTCTL reset 0xC — UART Alternate Control/Status Register
  fields as UART0.UART_ALTCTL
0x30 UART_FUNCSEL — UART Function Select Register
  [1:0] FUNCSEL — Function Select
    0=UART function; 1=LIN function (Only Available in UART1/UART2 Channel); 2=IrDA function; 3=RS-485 function
